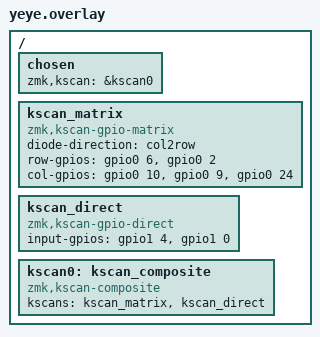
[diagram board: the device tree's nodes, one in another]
/dts-v1/;

/ {
    chosen {
        zmk,kscan = &kscan0;
    };

    kscan_matrix: kscan_matrix {
        compatible = "zmk,kscan-gpio-matrix";
        diode-direction = "col2row";

        row-gpios = <
            &gpio0 6 GPIO_ACTIVE_HIGH   // Row 0 (top)
            &gpio0 2 GPIO_ACTIVE_HIGH   // Row 1 (bottom)
        >;

        col-gpios = <
            &gpio0 10 (GPIO_PULL_DOWN | GPIO_ACTIVE_HIGH)  // Col 0
            &gpio0 9  (GPIO_PULL_DOWN | GPIO_ACTIVE_HIGH)  // Col 1
            &gpio0 24 (GPIO_PULL_DOWN | GPIO_ACTIVE_HIGH)  // Col 2
        >;
    };

    kscan_direct: kscan_direct {
        compatible = "zmk,kscan-gpio-direct";

        input-gpios =
            <&gpio1 4 (GPIO_PULL_DOWN | GPIO_ACTIVE_HIGH)>, // Direct key 1
            <&gpio1 0 (GPIO_PULL_DOWN | GPIO_ACTIVE_HIGH)>; // Direct key 2
    };

    kscan0: kscan_composite {
        compatible = "zmk,kscan-composite";
        kscans = <&kscan_matrix &kscan_direct>;
    };
};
